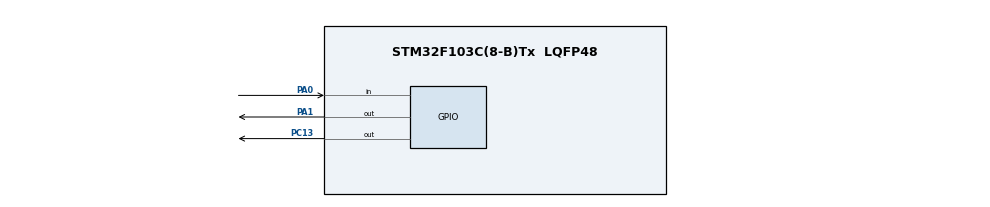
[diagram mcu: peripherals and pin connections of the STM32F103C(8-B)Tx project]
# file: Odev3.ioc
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Mcu.Family=STM32F1
Mcu.Name=STM32F103C(8-B)Tx
Mcu.Package=LQFP48
NVIC.PriorityGroup=NVIC_PRIORITYGROUP_4
NVIC.TIM2_IRQn=true\:0\:0\:false\:false\:true\:true\:true\:true
PA0-WKUP.GPIO_PuPd=GPIO_PULLUP
PA0-WKUP.Signal=GPIO_Input
PA1.Signal=GPIO_Output
PA13.Mode=Serial_Wire
PA13.Signal=SYS_JTMS-SWDIO
PA14.Mode=Serial_Wire
PA14.Signal=SYS_JTCK-SWCLK
PC13-TAMPER-RTC.Signal=GPIO_Output
ProjectManager.HeapSize=0x200
ProjectManager.StackSize=0x400
ProjectManager.TargetToolchain=STM32CubeIDE
RCC.APB1Freq_Value=8000000
RCC.APB2Freq_Value=8000000
TIM2.Period=999
TIM2.Prescaler=7999
VP_TIM2_VS_ClockSourceINT.Mode=Internal
board=custom

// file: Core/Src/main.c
/* USER CODE BEGIN Header */
/**
  ******************************************************************************
  * @file           : main.c
  * @brief          : Main program body
  ******************************************************************************
  * @attention
  *
  * Copyright (c) 2026 STMicroelectronics.
  * All rights reserved.
  *
  * This software is licensed under terms that can be found in the LICENSE file
  * in the root directory of this software component.
  * If no LICENSE file comes with this software, it is provided AS-IS.
  *
  ******************************************************************************
  */
/* USER CODE END Header */
#include "main.h"

TIM_HandleTypeDef htim2;

/* USER CODE BEGIN PV */

uint16_t blink_count = 4;     // Yanıp sönme sayısı
uint16_t current_blink = 0;   // Şu an kaçıncı yanıp sönmede
uint8_t led_state = 0;        // 0: Yanıp Sönme Modu, 1: 5sn Bekleme Modu
uint8_t wait_seconds = 0;     // Bekleme sayacı
uint8_t led_toggle_flag = 0;  // Yan-sön işlemi için bayrak
uint8_t button_pressed = 0;   // Buton durum kontrolü

/* USER CODE END PV */
/* USER CODE END PV */

void SystemClock_Config(void);
static void MX_GPIO_Init(void);
static void MX_TIM2_Init(void);

/* USER CODE BEGIN 0 */

// --- FLASH HAFIZA OKUMA VE YAZMA FONKSİYONLARI ---

#define FLASH_USER_ADDR 0x0800FC00 // Flash hafızada 63. sayfanın adresi (Güvenli bölge)

void Write_Flash(uint16_t data) {
    HAL_FLASH_Unlock(); // Hafıza kilidini aç
    FLASH_EraseInitTypeDef EraseInitStruct;
    uint32_t PageError = 0;

    EraseInitStruct.TypeErase   = FLASH_TYPEERASE_PAGES;
    EraseInitStruct.PageAddress = FLASH_USER_ADDR;
    EraseInitStruct.NbPages     = 1;

    // Önce o sayfayı sil
    HAL_FLASHEx_Erase(&EraseInitStruct, &PageError);
    // Sonra yeni değeri yaz
    HAL_FLASH_Program(FLASH_TYPEPROGRAM_HALFWORD, FLASH_USER_ADDR, data);

    HAL_FLASH_Lock(); // Hafızayı geri kilitle
}

uint16_t Read_Flash(void) {
    return *(__IO uint16_t*)FLASH_USER_ADDR; // Adresteki değeri oku
}

/* USER CODE END 0 */

int main(void)
{

  /* MCU Configuration--------------------------------------------------------*/

  /* Reset of all peripherals, Initializes the Flash interface and the Systick. */
  HAL_Init();

  /* Configure the system clock */
  SystemClock_Config();

  /* Initialize all configured peripherals */
  MX_GPIO_Init();
  MX_TIM2_Init();

  /* USER CODE BEGIN 2 */

  // 1. FABRİKA AYARLARINA DÖNÜŞ KONTROLÜ (Açılışta 3sn basılı tutulursa)
    if (HAL_GPIO_ReadPin(GPIOA, GPIO_PIN_0) == GPIO_PIN_RESET) {
        HAL_Delay(3000); // 3 saniye bekle
        // Eğer 3 saniye sonra hala basılıysa fabrika ayarına dön
        if (HAL_GPIO_ReadPin(GPIOA, GPIO_PIN_0) == GPIO_PIN_RESET) {
            Write_Flash(4);
        }
    }

    // 2. FLASH HAFIZADAN DEĞERİ OKU
    blink_count = Read_Flash();

    // Eğer hafıza boşsa (0xFFFF) veya değer 7'den büyük saçma bir sayıysa
    if (blink_count < 4 || blink_count > 7) {
        blink_count = 4;
        Write_Flash(blink_count); // 4 olarak düzeltip kaydet
    }

    // 3. ZAMANLAYICIYI BAŞLAT
    HAL_TIM_Base_Start_IT(&htim2);

  /* USER CODE END 2 */

  /* Infinite loop */
  while (1)
  {

    /* USER CODE BEGIN 3 */

	  if (HAL_GPIO_ReadPin(GPIOA, GPIO_PIN_0) == GPIO_PIN_RESET) {
	  	      HAL_Delay(50); // Debounce (Ark önleme)
	  	      if (HAL_GPIO_ReadPin(GPIOA, GPIO_PIN_0) == GPIO_PIN_RESET && button_pressed == 0) {
	  	          button_pressed = 1;

	  	          blink_count++; // Sayıyı artır
	  	          if (blink_count > 7) blink_count = 4; // 7'yi geçerse 4'e dön

	  	          Write_Flash(blink_count); // Yeni sayıyı Flash hafızaya KAYDET

	  	          // Butona basıldığında döngü temiz başlasın diye sıfırlamalar:
	  	          led_state = 0;
	  	          current_blink = 0;
	  	          led_toggle_flag = 0;
	  	          wait_seconds = 0;
	  	          HAL_GPIO_WritePin(GPIOC, GPIO_PIN_13, GPIO_PIN_SET); // LED sönsün
	  	      }
	  	  } else {
	  	      button_pressed = 0; // Elini çekince yeni basışa izin ver
	  	  }
	    }
  /* USER CODE END 3 */
}

void SystemClock_Config(void)
{
  RCC_OscInitTypeDef RCC_OscInitStruct = {0};
  RCC_ClkInitTypeDef RCC_ClkInitStruct = {0};

  /** Initializes the RCC Oscillators according to the specified parameters
  * in the RCC_OscInitTypeDef structure.
  */
  RCC_OscInitStruct.OscillatorType = RCC_OSCILLATORTYPE_HSI;
  RCC_OscInitStruct.HSIState = RCC_HSI_ON;
  RCC_OscInitStruct.HSICalibrationValue = RCC_HSICALIBRATION_DEFAULT;
  RCC_OscInitStruct.PLL.PLLState = RCC_PLL_NONE;
  if (HAL_RCC_OscConfig(&RCC_OscInitStruct) != HAL_OK)
  {
    Error_Handler();
  }

  /** Initializes the CPU, AHB and APB buses clocks
  */
  RCC_ClkInitStruct.ClockType = RCC_CLOCKTYPE_HCLK|RCC_CLOCKTYPE_SYSCLK
                              |RCC_CLOCKTYPE_PCLK1|RCC_CLOCKTYPE_PCLK2;
  RCC_ClkInitStruct.SYSCLKSource = RCC_SYSCLKSOURCE_HSI;
  RCC_ClkInitStruct.AHBCLKDivider = RCC_SYSCLK_DIV1;
  RCC_ClkInitStruct.APB1CLKDivider = RCC_HCLK_DIV1;
  RCC_ClkInitStruct.APB2CLKDivider = RCC_HCLK_DIV1;

  if (HAL_RCC_ClockConfig(&RCC_ClkInitStruct, FLASH_LATENCY_0) != HAL_OK)
  {
    Error_Handler();
  }
}

static void MX_TIM2_Init(void)
{

  TIM_ClockConfigTypeDef sClockSourceConfig = {0};
  TIM_MasterConfigTypeDef sMasterConfig = {0};

  htim2.Instance = TIM2;
  htim2.Init.Prescaler = 7999;
  htim2.Init.CounterMode = TIM_COUNTERMODE_UP;
  htim2.Init.Period = 999;
  htim2.Init.ClockDivision = TIM_CLOCKDIVISION_DIV1;
  htim2.Init.AutoReloadPreload = TIM_AUTORELOAD_PRELOAD_DISABLE;
  if (HAL_TIM_Base_Init(&htim2) != HAL_OK)
  {
    Error_Handler();
  }
  sClockSourceConfig.ClockSource = TIM_CLOCKSOURCE_INTERNAL;
  if (HAL_TIM_ConfigClockSource(&htim2, &sClockSourceConfig) != HAL_OK)
  {
    Error_Handler();
  }
  sMasterConfig.MasterOutputTrigger = TIM_TRGO_RESET;
  sMasterConfig.MasterSlaveMode = TIM_MASTERSLAVEMODE_DISABLE;
  if (HAL_TIMEx_MasterConfigSynchronization(&htim2, &sMasterConfig) != HAL_OK)
  {
    Error_Handler();
  }

}

static void MX_GPIO_Init(void)
{
  GPIO_InitTypeDef GPIO_InitStruct = {0};

  /* GPIO Ports Clock Enable */
  __HAL_RCC_GPIOC_CLK_ENABLE();
  __HAL_RCC_GPIOA_CLK_ENABLE();

  /*Configure GPIO pin Output Level */
  HAL_GPIO_WritePin(GPIOC, GPIO_PIN_13, GPIO_PIN_RESET);

  /*Configure GPIO pin Output Level */
  HAL_GPIO_WritePin(GPIOA, GPIO_PIN_1, GPIO_PIN_RESET);

  /*Configure GPIO pin : PC13 */
  GPIO_InitStruct.Pin = GPIO_PIN_13;
  GPIO_InitStruct.Mode = GPIO_MODE_OUTPUT_PP;
  GPIO_InitStruct.Pull = GPIO_NOPULL;
  GPIO_InitStruct.Speed = GPIO_SPEED_FREQ_LOW;
  HAL_GPIO_Init(GPIOC, &GPIO_InitStruct);

  /*Configure GPIO pin : PA0 */
  GPIO_InitStruct.Pin = GPIO_PIN_0;
  GPIO_InitStruct.Mode = GPIO_MODE_INPUT;
  GPIO_InitStruct.Pull = GPIO_PULLUP;
  HAL_GPIO_Init(GPIOA, &GPIO_InitStruct);

  /*Configure GPIO pin : PA1 */
  GPIO_InitStruct.Pin = GPIO_PIN_1;
  GPIO_InitStruct.Mode = GPIO_MODE_OUTPUT_PP;
  GPIO_InitStruct.Pull = GPIO_NOPULL;
  GPIO_InitStruct.Speed = GPIO_SPEED_FREQ_LOW;
  HAL_GPIO_Init(GPIOA, &GPIO_InitStruct);

}

/* USER CODE BEGIN 4 */
void HAL_TIM_PeriodElapsedCallback(TIM_HandleTypeDef *htim) {
    if (htim->Instance == TIM2) {

        if (led_state == 0) { // YANIP SÖNME AŞAMASI
            if (led_toggle_flag == 0) {
                HAL_GPIO_WritePin(GPIOC, GPIO_PIN_13, GPIO_PIN_RESET); // LED YAN
                led_toggle_flag = 1;
            } else {
                HAL_GPIO_WritePin(GPIOC, GPIO_PIN_13, GPIO_PIN_SET); // LED SÖN
                led_toggle_flag = 0;
                current_blink++; // 1 tam yanıp sönme tamamlandı

                if (current_blink >= blink_count) { // İstenen sayıya ulaştı mı?
                    led_state = 1; // Ulaştıysa 5 Saniye bekleme aşamasına geç
                    current_blink = 0;
                    wait_seconds = 0;
                }
            }
        }
        else if (led_state == 1) { // 5 SANİYE BEKLEME AŞAMASI
            HAL_GPIO_WritePin(GPIOC, GPIO_PIN_13, GPIO_PIN_SET); // LED kesin sönük
            wait_seconds++;

            if (wait_seconds >= 5) {
                led_state = 0; // 5 saniye bitti, baştan yanıp sönmeye başla
                wait_seconds = 0;
            }
        }

    }
}
/* USER CODE END 4 */

void Error_Handler(void)
{
  __disable_irq();
  while (1)
  {
  }
}
